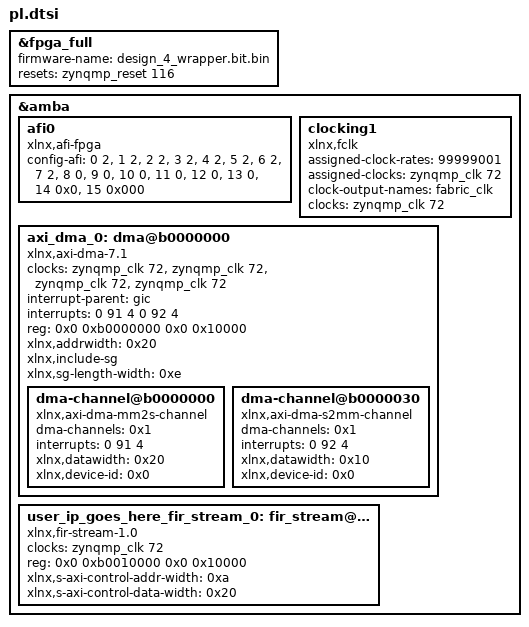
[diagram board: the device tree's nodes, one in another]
/*
 * CAUTION: This file is automatically generated by Xilinx.
 * Version: XSCT 2021.2
 * Today is: Sun Apr 16 15:19:38 2023
 */


/dts-v1/;
/plugin/;
/ {
	fragment@0 {
		target = <&fpga_full>;
		overlay0: __overlay__ {
			#address-cells = <2>;
			#size-cells = <2>;
			firmware-name = "design_4_wrapper.bit.bin";
			resets = <&zynqmp_reset 116>;
		};
	};
	fragment@1 {
		target = <&amba>;
		overlay1: __overlay__ {
			afi0: afi0 {
				compatible = "xlnx,afi-fpga";
				config-afi = < 0 2>, <1 2>, <2 2>, <3 2>, <4 2>, <5 2>, <6 2>, <7 2>, <8 0>, <9 0>, <10 0>, <11 0>, <12 0>, <13 0>, <14 0x0>, <15 0x000>;
			};
			clocking1: clocking1 {
				#clock-cells = <0>;
				assigned-clock-rates = <99999001>;
				assigned-clocks = <&zynqmp_clk 72>;
				clock-output-names = "fabric_clk";
				clocks = <&zynqmp_clk 72>;
				compatible = "xlnx,fclk";
			};
		};
	};
	fragment@2 {
		target = <&amba>;
		overlay2: __overlay__ {
			#address-cells = <2>;
			#size-cells = <2>;
			axi_dma_0: dma@b0000000 {
				#dma-cells = <1>;
				clock-names = "s_axi_lite_aclk", "m_axi_sg_aclk", "m_axi_mm2s_aclk", "m_axi_s2mm_aclk";
				clocks = <&zynqmp_clk 72>, <&zynqmp_clk 72>, <&zynqmp_clk 72>, <&zynqmp_clk 72>;
				compatible = "xlnx,axi-dma-7.1", "xlnx,axi-dma-1.00.a";
				interrupt-names = "mm2s_introut", "s2mm_introut";
				interrupt-parent = <&gic>;
				interrupts = <0 91 4 0 92 4>;
				reg = <0x0 0xb0000000 0x0 0x10000>;
				xlnx,addrwidth = <0x20>;
				xlnx,include-sg ;
				xlnx,sg-length-width = <0xe>;
				dma-channel@b0000000 {
					compatible = "xlnx,axi-dma-mm2s-channel";
					dma-channels = <0x1>;
					interrupts = <0 91 4>;
					xlnx,datawidth = <0x20>;
					xlnx,device-id = <0x0>;
				};
				dma-channel@b0000030 {
					compatible = "xlnx,axi-dma-s2mm-channel";
					dma-channels = <0x1>;
					interrupts = <0 92 4>;
					xlnx,datawidth = <0x10>;
					xlnx,device-id = <0x0>;
				};
			};
			user_ip_goes_here_fir_stream_0: fir_stream@b0010000 {
				/* This is a place holder node for a custom IP, user may need to update the entries */
				clock-names = "ap_clk";
				clocks = <&zynqmp_clk 72>;
				compatible = "xlnx,fir-stream-1.0";
				reg = <0x0 0xb0010000 0x0 0x10000>;
				xlnx,s-axi-control-addr-width = <0xa>;
				xlnx,s-axi-control-data-width = <0x20>;
			};
		};
	};
};
